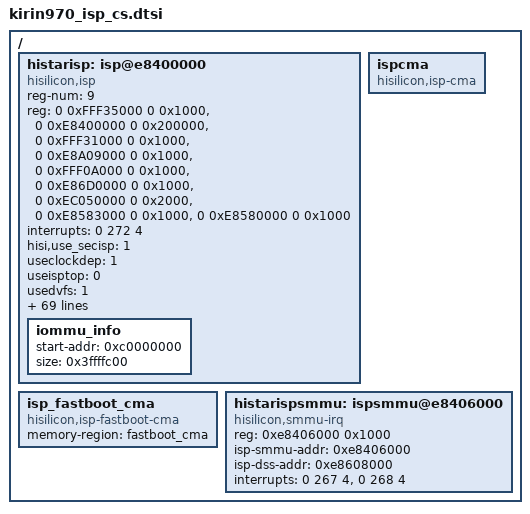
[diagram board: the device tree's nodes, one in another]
/*
 * Copyright (c) 2012-2013, The Linux Foundation. All rights reserved.
 *
 * This program is free software; you can redistribute it and/or modify
 * it under the terms of the GNU General Public License version 2 and
 * only version 2 as published by the Free Software Foundation.
 *
 * This program is distributed in the hope that it will be useful,
 * but WITHOUT ANY WARRANTY; without even the implied warranty of
 * MERCHANTABILITY or FITNESS FOR A PARTICULAR PURPOSE.  See the
 * GNU General Public License for more details.
 */
/ {
    histarisp: isp@e8400000 {
        compatible          = "hisilicon,isp";
        status              = "okay";       /* ("okay"/"disabled") When Disable Enumerating Device, Repace by "disabled". */

        /* Resource Items */
        reg-num             = <9>;          /* Resource Number of reg */
        reg = <0 0xFFF35000 0 0x1000>,      /* Resource Register 01 PERI_CRG */
              <0 0xE8400000 0 0x200000>,    /* Resource Register 02 ISP_Core_CFG */
              <0 0xFFF31000 0 0x1000>,      /* Resource Register 03 PMC */
              <0 0xE8A09000 0 0x1000>,      /* Resource Register 04 PCTRL */
              <0 0xFFF0A000 0 0x1000>,      /* Resource Register 05 SCTRL */
              <0 0xE86D0000 0 0x1000>,      /* Resource Register 06 NOC_ISP_Service_Target */
              <0 0xEC050000 0 0x2000>,      /* Resource Register 07 CSSYS */
              <0 0xE8583000 0 0x1000>,      /* Resource Register 08 ISP_SUB_CTRL */
              <0 0xE8580000 0 0x1000>;      /* Resource Register 09 ISP_WDT */
        interrupts          = <0 272 4>;    /* Resource IRQ */

        /* Switch Items */
        hisi,use_secisp     = <1>;          /* Switch 01 for Whether Support Trusted-Nontrus ISP or Not */
        useclockdep         = <1>;          /* Switch 02 for Whether Clock Enable Depend on Powerup or Not */
        useisptop           = <0>;          /* Switch 03 for Whether Use Top-powerup or Not */
        usedvfs             = <1>;          /* Switch 04 for Whether Use DVFS or Not */
        usepowerdn_clockdn  = <1>;          /* Switch 05 for Whether Need Clock Down When Power Down */
        sec-verify          = <1>;          /* Switch 06 for Whether Need Trusted Verify or Not */
        isp-reset-flag      = <1>;          /* Switch 07 for Whether Use ispCPU Reset or Not */
        isppd-adb-flag      = <0>;          /* Switch 08 for Whether Use ADB or Not */
        isp-wdt-flag        = <1>;          /* Switch 09 for Whether Use Watch Dog or Not */
        ispsmmu-init-byap   = <0>;          /* Switch 10 for Whether Smmu Init by AP or Not */
        isp-mdc-flag        = <1>;          /* Switch 11 for Whether Use MDC or Not */
        isp-efuse-flag      = <1>;          /* Switch 12 for Whether Use efuse_deskew or Not */

        /* Misc Items */
        isp-names           = "ISPCPU";     /* Name of MPU */
        firmware-names      = "isp_fw.elf"; /* Name of Firmware */
        bootware-names      = "isp_bw.elf"; /* Name of Bootware */
        mailbox-names       = "isp_mailbox";/* Name of IPC */
        isp-remap-addr      = <0x00000000>; /* Base Address for MPU Remap */
        isp-ipc-addr        = <0xC2020000>; /* Base Address for IPC Buffers(VA) */

        /* Isp Cpu Cfg */
        isp_local_timer     = <19200000>;   /* Isp Cpu Local Timer */

        /* Regulator Items */
        isp-clockdep-supply = <&ispsubsys>; /* Regulator for Clock Dependent */
        isp-core-supply     = <&isp_srt>;   /* Regulator for Core */

        /* Clock Items */
        clock-num           = <5>;                                                              	/* Clock Number */
        clocks              = <&clk_gate_ispcpu>,                                               	/* Clock Gate 01 for ispcpu */
                              <&clk_gate_ispfunc>,                                              	/* Clock Gate 02 for ispfunc */
                              <&clk_gate_ispi2c>,                                               	/* Clock Gate 03 for ispi2c */
                              <&clk_gate_vivobus>,                                               	/* Clock Gate 04 for vivobus */
                              <&clk_gate_isp_sys>;                                              	/* Clock Gate 05 for isp_sys  */
        clock-names         = "ispcpu", "ispfunc", "ispi2c", "vivobus", "isp_sys";                      /* Clock Names */
        clock-value         = <900000000 554000000 110670000 600000000 0>;                           	/* Clock Values for CLKLVL_TURBO */
        clkdn-normal        = <830000000 480000000 110670000 415000000 0>;                           	/* Clock Values for CLKLVL_NORMINAL, Control by usedvfs */
        clkdn-svs           = <600000000 300000000 110670000 300000000 0>;                           	/* Clock Values for CLKLVL_SVS, Control by usedvfs */
        clkdis-dvfs         = <415000000 238000000 19200000  300000000 0>;                           	/* Clock Values for CLKLVL_DISCLKDN, Control by usepowerdn_clockdn_pll0 */
        ispa7-default-clk   = <800000000>;                                                          /* Default isp Clock */

        /* Trusted ISP Items */
        share-smem-size     = <0x00140000>;                                                         /* ISP Share Mem Size */
        rsctable-mem-offet  = <0x00003000>;                                                         /* ISP Rsctable Offset */
        rsctable-mem-size   = <0x00001000>;                                                         /* ISP Rsctable Size */
        trusted-smem-size   = <0x01000000>;                                                         /* Trusted ISP Mem Size */
        trusted-smem-num    = <4>;                                                                  /* Trusted ISP Space Offset Num */
        trusted-smem-offset = <0x00000000 0x00000800 0x00001000 0x00003000>;                        /* Trusted ISP Space Offset Info  */
        isp-iova-start      = <0xC8000000>;                                              			/* Trusted ISP Space Base Address */
        isp-iova-size       = <0x9000000>;                                               			/* Trusted ISP Space Size */
        mapping-num         = <14>;                                                      			/* Trusted ISP Number of mapping */
        mapping-items       = <5>;                                                       			/* Trusted ISP Max Items of mapping */
        a7-vaddr-boot       = <0xFFFF0000 0x00010000 0x00000305 0x00010000 0x00000000>;  			/* Trusted ISP Page Table Mapping 01 for Boot Space */
        a7-vaddr-text       = <0xC0300000 0x00500000 0x00000305 0x00010000 0x00000001>;  			/* Trusted ISP Page Table Mapping 02 for Text Segment */
        a7-vaddr-data       = <0xC0800000 0x00800000 0x00000107 0x00510000 0x00000001>;  			/* Trusted ISP Page Table Mapping 03 for Data Segment */
        a7-vaddr-pgd        = <0xC1000000 0x00002000 0x00000101 0x00000000 0x00000001>;  			/* Trusted ISP Page Table Mapping 04 for PGD Space */
        a7-vaddr-pmd        = <0xC1002000 0x00002000 0x00000101 0x00002000 0x00000001>;  			/* Trusted ISP Page Table Mapping 05 for PMD Space */
        a7-vaddr-pte        = <0xC1100000 0x00200000 0x00000101 0x00D10000 0x00000001>;  			/* Trusted ISP Page Table Mapping 06 for PTE Space */
        a7-vaddr-rdr        = <0xC1800000 0x00040000 0x00000007 0x00000000 0x00000001>;  			/* Trusted ISP Page Table Mapping 07 for RDR Space */
        a7-vaddr-shrd       = <0xC2000000 0x00001000 0x00000003 0x0000C000 0x00000001>;  			/* Trusted ISP Page Table Mapping 08 for Shared Memory */
        a7-vaddr-vq         = <0xC2020000 0x00040000 0x00000003 0x00000000 0x00000001>;  			/* Trusted ISP Page Table Mapping 09 for Virt Quene */
        a7-vaddr-vr0        = <0xC2060000 0x00003000 0x00000003 0x00000000 0x00000001>;  			/* Trusted ISP Page Table Mapping 10 for Virt Ring Buffer0 */
        a7-vaddr-vr1        = <0xC2063000 0x00003000 0x00000003 0x00000000 0x00000001>;  			/* Trusted ISP Page Table Mapping 11 for Virt Ring Buffer1 */
        a7-vaddr-heap       = <0xC4000000 0x04000000 0x00000107 0x00000000 0x00000001>;  			/* Trusted ISP Page Table Mapping 12 for OS Heap Memory Space */
        a7-vaddr-a7dyna     = <0xD1000000 0x0F000000 0x00000007 0x00000000 0x00000000>;  			/* Trusted ISP Page Table Mapping 13 for Dynamic Memory Space */
        a7-vaddr-mdc        = <0xC1400000 0x00100000 0x00000007 0x00000000 0x00000000>;  			/* Trusted ISP Page Table Mapping 14 for MDC Memory Space */
        /*                    <ispva      size       prot       offset     reserve   >*/

        /* Definition for Smmu/Iommu Driver */
        iommu_info {
            start-addr      = <0xc0000000>;
            size            = <0x3ffffc00>;
        };
    };

    ispcma {
        compatible = "hisilicon,isp-cma";
        status = "ok";
    };

    isp_fastboot_cma {
        compatible = "hisilicon,isp-fastboot-cma";
        memory-region = <&fastboot_cma>;
        status = "ok";
    };

    histarispsmmu: ispsmmu@e8406000 {
        compatible = "hisilicon,smmu-irq";
        reg = <0xe8406000 0x1000>;
            isp-smmu-addr = <0xe8406000>;
            isp-dss-addr  = <0xe8608000>;
        interrupts = <0 267 4>,<0 268 4>;
        status = "ok";
    };
};
